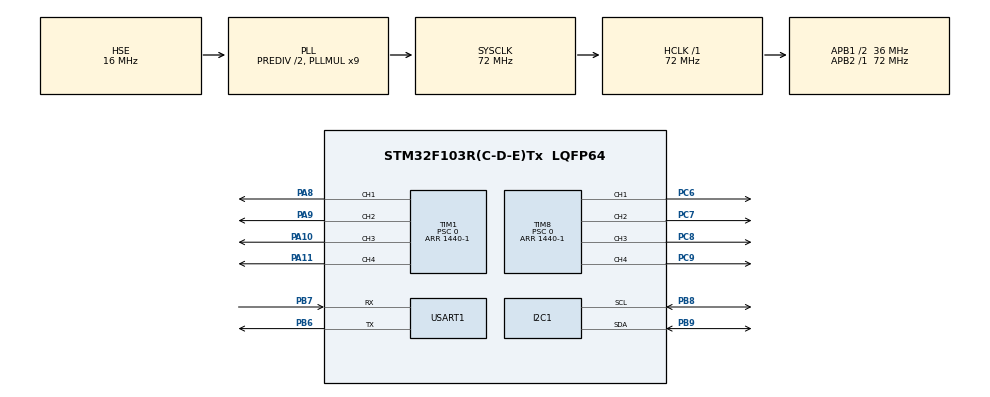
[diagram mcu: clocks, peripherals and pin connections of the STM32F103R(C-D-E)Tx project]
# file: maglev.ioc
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Dma.I2C1_RX.1.Direction=DMA_PERIPH_TO_MEMORY
Dma.I2C1_RX.1.Instance=DMA1_Channel7
Dma.I2C1_RX.1.MemDataAlignment=DMA_MDATAALIGN_BYTE
Dma.I2C1_RX.1.MemInc=DMA_MINC_ENABLE
Dma.I2C1_RX.1.Mode=DMA_NORMAL
Dma.I2C1_RX.1.PeriphDataAlignment=DMA_PDATAALIGN_BYTE
Dma.I2C1_RX.1.PeriphInc=DMA_PINC_DISABLE
Dma.I2C1_RX.1.Priority=DMA_PRIORITY_LOW
Dma.I2C1_TX.2.Direction=DMA_MEMORY_TO_PERIPH
Dma.I2C1_TX.2.Instance=DMA1_Channel6
Dma.I2C1_TX.2.MemDataAlignment=DMA_MDATAALIGN_BYTE
Dma.I2C1_TX.2.MemInc=DMA_MINC_ENABLE
Dma.I2C1_TX.2.Mode=DMA_NORMAL
Dma.I2C1_TX.2.PeriphDataAlignment=DMA_PDATAALIGN_BYTE
Dma.I2C1_TX.2.PeriphInc=DMA_PINC_DISABLE
Dma.I2C1_TX.2.Priority=DMA_PRIORITY_LOW
Dma.Request0=USART1_RX
Dma.Request1=I2C1_RX
Dma.Request2=I2C1_TX
Dma.Request3=USART1_TX
Dma.USART1_RX.0.Direction=DMA_PERIPH_TO_MEMORY
Dma.USART1_RX.0.Instance=DMA1_Channel5
Dma.USART1_RX.0.MemDataAlignment=DMA_MDATAALIGN_BYTE
Dma.USART1_RX.0.MemInc=DMA_MINC_ENABLE
Dma.USART1_RX.0.Mode=DMA_NORMAL
Dma.USART1_RX.0.PeriphDataAlignment=DMA_PDATAALIGN_BYTE
Dma.USART1_RX.0.PeriphInc=DMA_PINC_DISABLE
Dma.USART1_RX.0.Priority=DMA_PRIORITY_LOW
Dma.USART1_TX.3.Direction=DMA_MEMORY_TO_PERIPH
Dma.USART1_TX.3.Instance=DMA1_Channel4
Dma.USART1_TX.3.MemDataAlignment=DMA_MDATAALIGN_BYTE
Dma.USART1_TX.3.MemInc=DMA_MINC_ENABLE
Dma.USART1_TX.3.Mode=DMA_NORMAL
Dma.USART1_TX.3.PeriphDataAlignment=DMA_PDATAALIGN_BYTE
Dma.USART1_TX.3.PeriphInc=DMA_PINC_DISABLE
Dma.USART1_TX.3.Priority=DMA_PRIORITY_LOW
Mcu.Family=STM32F1
Mcu.Name=STM32F103R(C-D-E)Tx
Mcu.Package=LQFP64
NVIC.DMA1_Channel4_IRQn=true\:0\:0\:false\:false\:true\:false\:true\:true
NVIC.DMA1_Channel5_IRQn=true\:0\:0\:false\:false\:true\:false\:true\:true
NVIC.DMA1_Channel6_IRQn=true\:0\:0\:false\:false\:true\:false\:true\:true
NVIC.DMA1_Channel7_IRQn=true\:0\:0\:false\:false\:true\:false\:true\:true
NVIC.PriorityGroup=NVIC_PRIORITYGROUP_4
NVIC.TIM2_IRQn=true\:0\:0\:false\:false\:false\:true\:true\:true
PA10.GPIO_Speed=GPIO_SPEED_FREQ_MEDIUM
PA10.Signal=S_TIM1_CH3
PA11.GPIO_Speed=GPIO_SPEED_FREQ_MEDIUM
PA11.Signal=S_TIM1_CH4
PA13.Mode=Serial_Wire
PA13.Signal=SYS_JTMS-SWDIO
PA14.Mode=Serial_Wire
PA14.Signal=SYS_JTCK-SWCLK
PA8.GPIO_Speed=GPIO_SPEED_FREQ_MEDIUM
PA8.Signal=S_TIM1_CH1
PA9.GPIO_Speed=GPIO_SPEED_FREQ_MEDIUM
PA9.Signal=S_TIM1_CH2
PB6.Mode=Asynchronous
PB6.Signal=USART1_TX
PB7.Mode=Asynchronous
PB7.Signal=USART1_RX
PB8.Mode=I2C
PB8.Signal=I2C1_SCL
PB9.Mode=I2C
PB9.Signal=I2C1_SDA
PC6.GPIO_Speed=GPIO_SPEED_FREQ_MEDIUM
PC6.Signal=S_TIM8_CH1
PC7.GPIO_Speed=GPIO_SPEED_FREQ_MEDIUM
PC7.Signal=S_TIM8_CH2
PC8.GPIO_Speed=GPIO_SPEED_FREQ_MEDIUM
PC8.Signal=S_TIM8_CH3
PC9.GPIO_Speed=GPIO_SPEED_FREQ_MEDIUM
PC9.Signal=S_TIM8_CH4
PD0-OSC_IN.Mode=HSE-External-Oscillator
PD0-OSC_IN.Signal=RCC_OSC_IN
PD1-OSC_OUT.Mode=HSE-External-Oscillator
PD1-OSC_OUT.Signal=RCC_OSC_OUT
ProjectManager.HeapSize=0x200
ProjectManager.StackSize=0x400
ProjectManager.TargetToolchain=Makefile
RCC.AHBFreq_Value=72000000
RCC.APB1CLKDivider=RCC_HCLK_DIV2
RCC.APB1Freq_Value=36000000
RCC.APB1TimFreq_Value=72000000
RCC.APB2Freq_Value=72000000
RCC.APB2TimFreq_Value=72000000
RCC.HCLKFreq_Value=72000000
RCC.HSEDivPLL=RCC_HSE_PREDIV_DIV2
RCC.HSE_VALUE=16000000
RCC.PLLMUL=RCC_PLL_MUL9
RCC.PLLSourceVirtual=RCC_PLLSOURCE_HSE
RCC.SYSCLKFreq_VALUE=72000000
RCC.SYSCLKSource=RCC_SYSCLKSOURCE_PLLCLK
RCC.USBFreq_Value=72000000
SH.S_TIM1_CH1.0=TIM1_CH1,PWM Generation1 CH1
SH.S_TIM1_CH2.0=TIM1_CH2,PWM Generation2 CH2
SH.S_TIM1_CH3.0=TIM1_CH3,PWM Generation3 CH3
SH.S_TIM1_CH4.0=TIM1_CH4,PWM Generation4 CH4
SH.S_TIM8_CH1.0=TIM8_CH1,PWM Generation1 CH1
SH.S_TIM8_CH2.0=TIM8_CH2,PWM Generation2 CH2
SH.S_TIM8_CH3.0=TIM8_CH3,PWM Generation3 CH3
SH.S_TIM8_CH4.0=TIM8_CH4,PWM Generation4 CH4
TIM1.Channel-PWM\ Generation1\ CH1=TIM_CHANNEL_1
TIM1.Channel-PWM\ Generation2\ CH2=TIM_CHANNEL_2
TIM1.Channel-PWM\ Generation3\ CH3=TIM_CHANNEL_3
TIM1.Channel-PWM\ Generation4\ CH4=TIM_CHANNEL_4
TIM1.Period=1440-1
TIM1.Prescaler=0
TIM2.Period=100-1
TIM2.Prescaler=72-1
TIM8.Channel-PWM\ Generation1\ CH1=TIM_CHANNEL_1
TIM8.Channel-PWM\ Generation2\ CH2=TIM_CHANNEL_2
TIM8.Channel-PWM\ Generation3\ CH3=TIM_CHANNEL_3
TIM8.Channel-PWM\ Generation4\ CH4=TIM_CHANNEL_4
TIM8.Period=1440-1
TIM8.Prescaler=0
USART1.VirtualMode=VM_ASYNC
VP_TIM1_VS_ClockSourceINT.Mode=Internal
VP_TIM2_VS_ClockSourceINT.Mode=Internal
VP_TIM8_VS_ClockSourceINT.Mode=Internal
board=custom

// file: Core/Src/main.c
/* USER CODE BEGIN Header */
/**
  ******************************************************************************
  * @file           : main.c
  * @brief          : Main program body
  ******************************************************************************
  * @attention
  *
  * Copyright (c) 2026 STMicroelectronics.
  * All rights reserved.
  *
  * This software is licensed under terms that can be found in the LICENSE file
  * in the root directory of this software component.
  * If no LICENSE file comes with this software, it is provided AS-IS.
  *
  ******************************************************************************
  */
/* USER CODE END Header */
#include "main.h"
#include "dma.h"
#include "i2c.h"
#include "tim.h"
#include "usart.h"
#include "gpio.h"

void SystemClock_Config(void);
/* USER CODE BEGIN PFP */
extern void startup();
/* USER CODE END PFP */

int main(void)
{

  /* MCU Configuration--------------------------------------------------------*/

  /* Reset of all peripherals, Initializes the Flash interface and the Systick. */
  HAL_Init();

  /* Configure the system clock */
  SystemClock_Config();

  /* Initialize all configured peripherals */
  MX_GPIO_Init();
  MX_DMA_Init();
  MX_I2C1_Init();
  MX_TIM1_Init();
  MX_TIM8_Init();
  MX_USART1_UART_Init();
  MX_TIM2_Init();
  /* USER CODE BEGIN 2 */
  startup();
  /* USER CODE END 2 */

  /* Infinite loop */
  while (1)
  {

  }
}

void SystemClock_Config(void)
{
  RCC_OscInitTypeDef RCC_OscInitStruct = {0};
  RCC_ClkInitTypeDef RCC_ClkInitStruct = {0};

  /** Initializes the RCC Oscillators according to the specified parameters
  * in the RCC_OscInitTypeDef structure.
  */
  RCC_OscInitStruct.OscillatorType = RCC_OSCILLATORTYPE_HSE;
  RCC_OscInitStruct.HSEState = RCC_HSE_ON;
  RCC_OscInitStruct.HSEPredivValue = RCC_HSE_PREDIV_DIV2;
  RCC_OscInitStruct.HSIState = RCC_HSI_ON;
  RCC_OscInitStruct.PLL.PLLState = RCC_PLL_ON;
  RCC_OscInitStruct.PLL.PLLSource = RCC_PLLSOURCE_HSE;
  RCC_OscInitStruct.PLL.PLLMUL = RCC_PLL_MUL9;
  if (HAL_RCC_OscConfig(&RCC_OscInitStruct) != HAL_OK)
  {
    Error_Handler();
  }

  /** Initializes the CPU, AHB and APB buses clocks
  */
  RCC_ClkInitStruct.ClockType = RCC_CLOCKTYPE_HCLK|RCC_CLOCKTYPE_SYSCLK
                              |RCC_CLOCKTYPE_PCLK1|RCC_CLOCKTYPE_PCLK2;
  RCC_ClkInitStruct.SYSCLKSource = RCC_SYSCLKSOURCE_PLLCLK;
  RCC_ClkInitStruct.AHBCLKDivider = RCC_SYSCLK_DIV1;
  RCC_ClkInitStruct.APB1CLKDivider = RCC_HCLK_DIV2;
  RCC_ClkInitStruct.APB2CLKDivider = RCC_HCLK_DIV1;

  if (HAL_RCC_ClockConfig(&RCC_ClkInitStruct, FLASH_LATENCY_2) != HAL_OK)
  {
    Error_Handler();
  }
}

void Error_Handler(void)
{
  __disable_irq();
  while (1)
  {
  }
}
